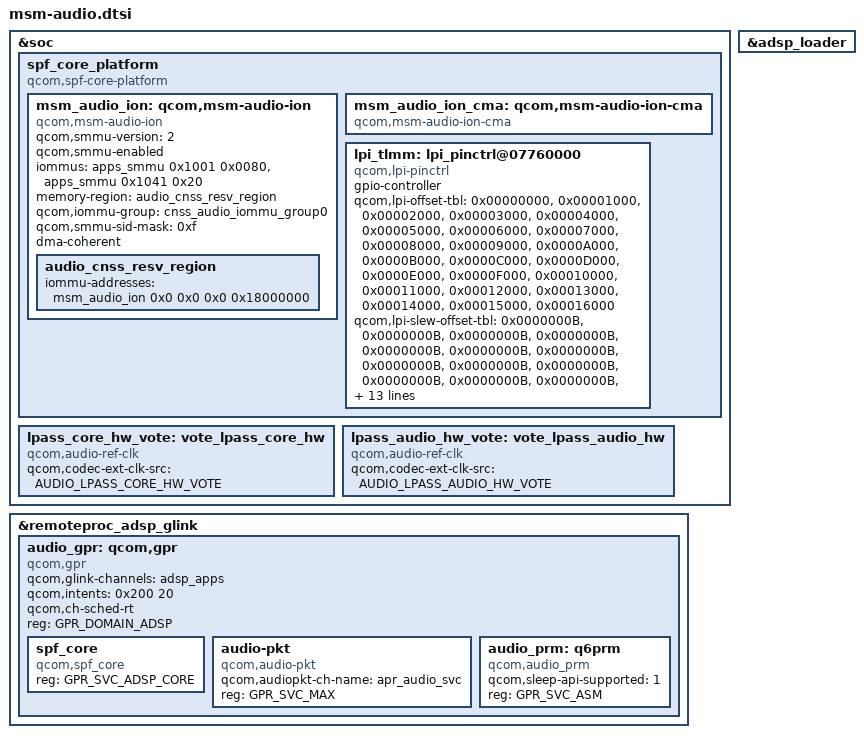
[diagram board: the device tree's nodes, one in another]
/*
 * Copyright (c) 2023-2025 Qualcomm Innovation Center, Inc. All rights reserved.
 */

#include <bindings/qcom,audio-ext-clk.h>
#include <bindings/qcom,gpr.h>
#include "msm-audio-lpass.dtsi"

&soc {
	spf_core_platform: spf_core_platform {
		compatible = "qcom,spf-core-platform";
	};

	lpass_core_hw_vote: vote_lpass_core_hw {
		compatible = "qcom,audio-ref-clk";
		qcom,codec-ext-clk-src = <AUDIO_LPASS_CORE_HW_VOTE>;
		#clock-cells = <1>;
	};

	lpass_audio_hw_vote: vote_lpass_audio_hw {
		compatible = "qcom,audio-ref-clk";
		qcom,codec-ext-clk-src = <AUDIO_LPASS_AUDIO_HW_VOTE>;
		#clock-cells = <1>;
	};
};

&remoteproc_adsp_glink {
	audio_gpr: qcom,gpr {
		compatible = "qcom,gpr";
		qcom,glink-channels = "adsp_apps";
		qcom,intents = <0x200 20>;
		qcom,ch-sched-rt;
		reg = <GPR_DOMAIN_ADSP>;

		spf_core {
			compatible = "qcom,spf_core";
			reg = <GPR_SVC_ADSP_CORE>;
		};

		audio-pkt {
			compatible = "qcom,audio-pkt";
			qcom,audiopkt-ch-name = "apr_audio_svc";
			reg = <GPR_SVC_MAX>;
		};

		audio_prm: q6prm {
			compatible = "qcom,audio_prm";
			qcom,sleep-api-supported = <1>;
			reg = <GPR_SVC_ASM>;
		};
	};
};

&spf_core_platform {
	#address-cells = <2>;
	#size-cells = <2>;

	msm_audio_ion: qcom,msm-audio-ion {
		compatible = "qcom,msm-audio-ion";
		qcom,smmu-version = <2>;
		qcom,smmu-enabled;
		iommus = <&apps_smmu 0x1001 0x0080>, <&apps_smmu 0x1041 0x20>;
		memory-region = <&audio_cnss_resv_region>;
		qcom,iommu-group = <&cnss_audio_iommu_group0>;
		qcom,smmu-sid-mask = /bits/ 64 <0xf>;
		dma-coherent;
		audio_cnss_resv_region: audio_cnss_resv_region {
			iommu-addresses = <&msm_audio_ion 0x0 0x0 0x0 0x18000000>;
		};
	};

	msm_audio_ion_cma: qcom,msm-audio-ion-cma {
		compatible = "qcom,msm-audio-ion-cma";
	};

	lpi_tlmm: lpi_pinctrl@07760000 {
		compatible = "qcom,lpi-pinctrl";
		gpio-controller;
		#gpio-cells = <2>;
		qcom,lpi-offset-tbl = <0x00000000>, <0x00001000>,
					<0x00002000>, <0x00003000>,
					<0x00004000>, <0x00005000>,
					<0x00006000>, <0x00007000>,
					<0x00008000>, <0x00009000>,
					<0x0000A000>, <0x0000B000>,
					<0x0000C000>, <0x0000D000>,
					<0x0000E000>, <0x0000F000>,
					<0x00010000>, <0x00011000>,
					<0x00012000>, <0x00013000>,
					<0x00014000>, <0x00015000>,
					<0x00016000>;
		qcom,lpi-slew-offset-tbl = <0x0000000B>, <0x0000000B>,
						<0x0000000B>, <0x0000000B>,
						<0x0000000B>, <0x0000000B>,
						<0x0000000B>, <0x0000000B>,
						<0x0000000B>, <0x0000000B>,
						<0x0000000B>, <0x0000000B>,
						<0x0000000B>, <0x0000000B>,
						<0x0000000B>, <0x0000000B>,
						<0x0000000B>, <0x0000000B>,
						<0x0000000B>, <0x0000000B>,
						<0x0000000B>, <0x0000000B>,
						<0x0000000B>;

		qcom,lpi-slew-base-tbl = <0x7760000>, <0x7761000>,
						<0x7762000>, <0x7763000>,
						<0x7764000>, <0x7765000>,
						<0x7766000>, <0x7767000>,
						<0x7768000>, <0x7769000>,
						<0x776A000>, <0x776B000>,
						<0x776C000>, <0x776D000>,
						<0x776E000>, <0x776F000>,
						<0x7770000>, <0x7771000>,
						<0x7772000>, <0x7773000>,
						<0x7774000>, <0x7775000>,
						<0x7776000>;

		clock-names = "lpass_core_hw_vote",
				"lpass_audio_hw_vote";
		clocks = <&lpass_core_hw_vote 0>,
				<&lpass_audio_hw_vote 0>;
	};
};
&adsp_loader {
	/delete-property/ qcom,adsp-state;
};
